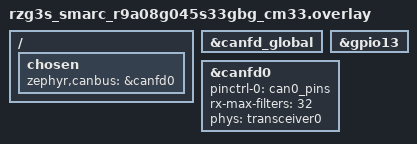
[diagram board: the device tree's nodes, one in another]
/ {
	chosen {
		zephyr,canbus = &canfd0;
	};
};

&canfd_global {
	status = "okay";
};

&gpio13{
	status = "okay";
};

&canfd0 {
	pinctrl-0 = <&can0_pins>;
	pinctrl-names = "default";
	status = "okay";
	rx-max-filters = <32>;
	phys = <&transceiver0>;
};
